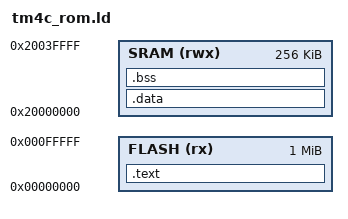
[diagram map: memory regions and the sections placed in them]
/******************************************************************************
 *
 * blinky.ld - Linker configuration file for blinky.
 *
 * Copyright (c) 2013-2017 Texas Instruments Incorporated.  All rights reserved.
 * Software License Agreement
 * 
 * Texas Instruments (TI) is supplying this software for use solely and
 * exclusively on TI's microcontroller products. The software is owned by
 * TI and/or its suppliers, and is protected under applicable copyright
 * laws. You may not combine this software with "viral" open-source
 * software in order to form a larger program.
 * 
 * THIS SOFTWARE IS PROVIDED "AS IS" AND WITH ALL FAULTS.
 * NO WARRANTIES, WHETHER EXPRESS, IMPLIED OR STATUTORY, INCLUDING, BUT
 * NOT LIMITED TO, IMPLIED WARRANTIES OF MERCHANTABILITY AND FITNESS FOR
 * A PARTICULAR PURPOSE APPLY TO THIS SOFTWARE. TI SHALL NOT, UNDER ANY
 * CIRCUMSTANCES, BE LIABLE FOR SPECIAL, INCIDENTAL, OR CONSEQUENTIAL
 * DAMAGES, FOR ANY REASON WHATSOEVER.
 * 
 * This is part of revision 2.1.4.178 of the DK-TM4C129X Firmware Package.
 *
 *****************************************************************************/

MEMORY
{
    FLASH (rx) : ORIGIN = 0x00000000, LENGTH = 0x00100000
    SRAM (rwx) : ORIGIN = 0x20000000, LENGTH = 0x00040000
}

SECTIONS
{
    .text :
    {
        _text = .;
        KEEP(*(.isr_vector))
        *(.text*)
        *(.rodata*)
		
		/* section information for finsh shell */
        . = ALIGN(4);
        __fsymtab_start = .;
        KEEP(*(FSymTab))
        __fsymtab_end = .;
        . = ALIGN(4);
        __vsymtab_start = .;
        KEEP(*(VSymTab))
        __vsymtab_end = .;
        . = ALIGN(4);

        /* section information for initial. */
        . = ALIGN(4);
        __rt_init_start = .;
        KEEP(*(SORT(.rti_fn*)))
        __rt_init_end = .;
        . = ALIGN(4);
		
        _etext = .;
    } > FLASH

    .data : AT(ADDR(.text) + SIZEOF(.text))
    {
        _data = .;
        _ldata = LOADADDR (.data);
        *(vtable)
        *(.data*)
        _edata = .;
    } > SRAM

    .bss :
    {
        _bss = .;
        *(.bss*)
        *(COMMON)
        _ebss = .;
    } > SRAM
}
